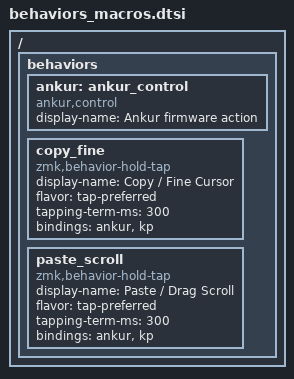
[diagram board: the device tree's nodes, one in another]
#include <dt-bindings/zmk/keys.h>
#include <dt-bindings/ankur/actions.h>

/ {
	behaviors {
		ankur: ankur_control {
			compatible = "ankur,control";
			display-name = "Ankur firmware action";
			#binding-cells = <1>;
		};

		copy_fine: copy_fine {
			compatible = "zmk,behavior-hold-tap";
			display-name = "Copy / Fine Cursor";
			#binding-cells = <2>;
			flavor = "tap-preferred";
			tapping-term-ms = <300>;
			bindings = <&ankur>, <&kp>;
		};

		paste_scroll: paste_scroll {
			compatible = "zmk,behavior-hold-tap";
			display-name = "Paste / Drag Scroll";
			#binding-cells = <2>;
			flavor = "tap-preferred";
			tapping-term-ms = <300>;
			bindings = <&ankur>, <&kp>;
		};
	};
};
